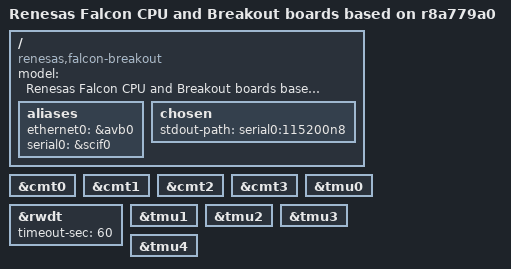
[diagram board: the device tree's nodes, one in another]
// SPDX-License-Identifier: GPL-2.0
/*
 * Device Tree Source for the Falcon CPU and BreakOut boards
 *
 * Copyright (C) 2020 Renesas Electronics Corp.
 */

/dts-v1/;
#include "r8a779a0-falcon-cpu.dtsi"

/ {
	model = "Renesas Falcon CPU and Breakout boards based on r8a779a0";
	compatible = "renesas,falcon-breakout", "renesas,falcon-cpu", "renesas,r8a779a0";

	aliases {
		ethernet0 = &avb0;
		serial0 = &scif0;
	};

	chosen {
		stdout-path = "serial0:115200n8";
	};
};

&cmt0 {
	status = "okay";
};

&cmt1 {
	status = "okay";
};

&cmt2 {
	status = "okay";
};

&cmt3 {
	status = "okay";
};

&rwdt {
	timeout-sec = <60>;
	status = "okay";
};

&tmu0 {
	status = "okay";
};

&tmu1 {
	status = "okay";
};

&tmu2 {
	status = "okay";
};

&tmu3 {
	status = "okay";
};

&tmu4 {
	status = "okay";
};
